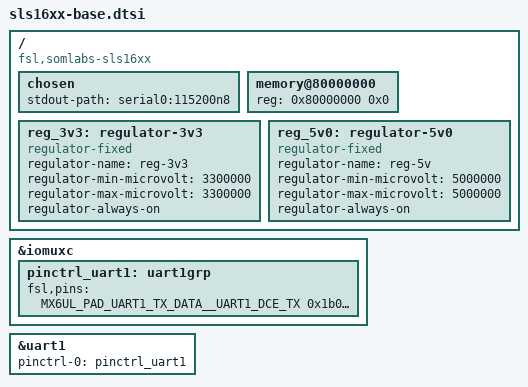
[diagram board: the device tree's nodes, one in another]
/*
 * This program is free software; you can redistribute it and/or modify
 * it under the terms of the GNU General Public License version 2 as
 * published by the Free Software Foundation.
 */

#include "imx6ull.dtsi"

/ {
	compatible = "fsl,somlabs-sls16xx", "fsl,imx6ull";

	chosen {
		stdout-path = "serial0:115200n8";
	};

	/* RAM */
	memory@80000000 {
		device_type = "memory";
		reg = <0x80000000 0x0>;
	};

	/* 3.3V */
	reg_3v3: regulator-3v3 {
		compatible = "regulator-fixed";
		regulator-name = "reg-3v3";
		regulator-min-microvolt = <3300000>;
		regulator-max-microvolt = <3300000>;
		regulator-always-on;
	};

	/* 5V */
	reg_5v0: regulator-5v0 {
		compatible = "regulator-fixed";
		regulator-name = "reg-5v";
		regulator-min-microvolt = <5000000>;
		regulator-max-microvolt = <5000000>;
		regulator-always-on;
	};
};

/* IO multiplexing */
&iomuxc {
	/* Console */
	pinctrl_uart1: uart1grp {
		fsl,pins = <
			MX6UL_PAD_UART1_TX_DATA__UART1_DCE_TX 0x1b0b1
			MX6UL_PAD_UART1_RX_DATA__UART1_DCE_RX 0x1b0b1
		>;
	};
};

/* Console */
&uart1 {
	pinctrl-names = "default";
	pinctrl-0 = <&pinctrl_uart1>;
	status = "okay";
};
